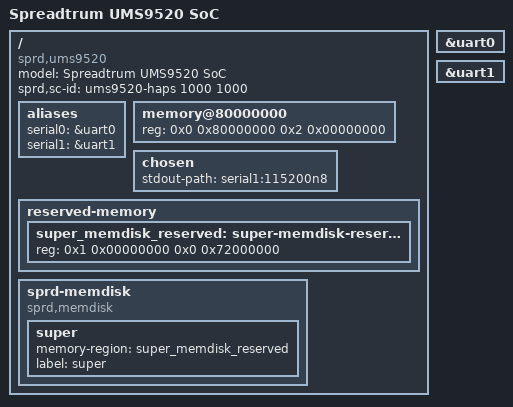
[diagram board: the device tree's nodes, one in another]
// SPDX-License-Identifier: GPL-2.0-only
/*
 * Unisoc Qogirl6pro platform DTS file
 *
 * Copyright (C) 2020, Unisoc Inc.
 */

/dts-v1/;

#include "ums9520-haps.dtsi"
#include "ums9520-haps-mach.dtsi"

/ {
	model = "Spreadtrum UMS9520 SoC";

	compatible = "sprd,ums9520";

	sprd,sc-id = "ums9520-haps 1000 1000";

	aliases {
		serial0 = &uart0;
		serial1 = &uart1;
	};

	memory@80000000 {
		device_type = "memory";
		reg = <0x0 0x80000000 0x2 0x00000000>;
	};

	chosen: chosen {
		stdout-path = "serial1:115200n8";
	};
	reserved-memory {
		#address-cells = <2>;
		#size-cells = <2>;
		ranges;

		super_memdisk_reserved: super-memdisk-reserved@100000000{
			reg = <0x1 0x00000000 0x0 0x72000000>;	/* super 1800M */
		};
};

	sprd-memdisk {
		compatible = "sprd,memdisk";

		super {
			memory-region = <&super_memdisk_reserved>;
			label = "super";
		};

	};
};

&uart0 {
	status = "okay";
};

&uart1 {
	status = "okay";
};
